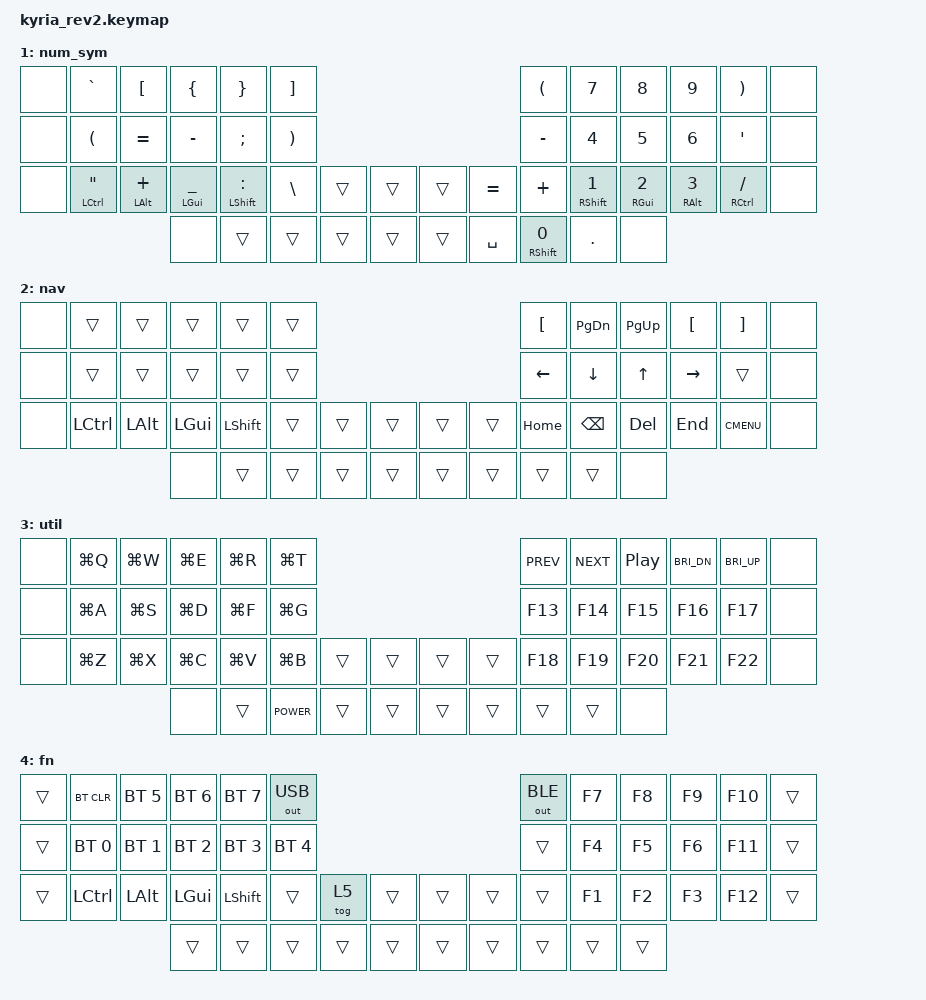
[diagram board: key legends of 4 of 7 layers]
/*
 * Copyright (c) 2020 The ZMK Contributors
 *
 * SPDX-License-Identifier: MIT
 */

#include <behaviors.dtsi>
#include <dt-bindings/zmk/keys.h>
#include <dt-bindings/zmk/bt.h>
#include <dt-bindings/zmk/outputs.h>
#include <dt-bindings/zmk/ext_power.h>

/ {
    behaviors {
        hrml: homerowmods_left {
            compatible = "zmk,behavior-hold-tap";
            label = "HOMEROW_MODS_LEFT";
            #binding-cells = <2>;
            flavor = "tap-preferred";
            require-prior-idle-ms = <120>;
            tapping-term-ms = <200>;
            quick-tap-ms = <100>;
            global-quick-tap;
            bindings =
                <&kp>,
                <&kp>;

            /* hold-trigger-key-positions = <1 2  4  6 7 8 9 10 11  13 14 15 16 19 20 21 22 23 24  26 27 28 29  31 32 33 34 35 36 40 41 42>; */
            hold-trigger-key-positions = <6 7 8 9 10 11 19 20 21 22 23 24 31 32 33 34 35 36 40 41 42>;
            hold-trigger-on-release;
        };
        hrmr: homerowmods_right {
            compatible = "zmk,behavior-hold-tap";
            label = "HOMEROW_MODS_RIGHT";
            #binding-cells = <2>;
            flavor = "tap-preferred";
            require-prior-idle-ms = <120>;
            tapping-term-ms = <200>;
            quick-tap-ms = <100>;
            global-quick-tap;
            bindings =
                <&kp>,
                <&kp>;

            /* hold-trigger-key-positions = <0 1 2 3 4 5 12 13 14 15 16 17 25 26 27 28 29 30  32 33 34 35  37 38 39>; */
            hold-trigger-key-positions = <0 1 2 3 4 5 12 13 14 15 16 17 25 26 27 28 29 30 37 38 39>;
            hold-trigger-on-release;
        };
    };

    combos {
        compatible = "zmk,combos";

        // semicolon_fr {
        //     bindings = <&kp SEMICOLON>;
        //     key-positions = <4 16>;
        //     timeout-ms = <30>;
        // };

        enter_kl {
            bindings = <&kp ENTER>;
            key-positions = <20 21>;
            timeout-ms = <20>;
        };

        backspace_jl {
            bindings = <&kp BACKSPACE>;
            key-positions = <19 21>;
            timeout-ms = <40>;
        };

        backspace_jk {
            bindings = <&kp LA(BACKSPACE)>;
            key-positions = <19 20>;
            timeout-ms = <30>;
        };

        tab_df {
            bindings = <&kp TAB>;
            key-positions = <15 16>;
            timeout-ms = <40>;
            layers = <0 1 2 3>;
        };

        escape_uio {
            bindings = <&kp ESCAPE>;
            key-positions = <7 8 9>;
            timeout-ms = <30>;
        };

        enter_sd {
            bindings = <&kp ENTER>;
            key-positions = <14 15>;
            timeout-ms = <20>;
            layers = <0 1 2 3>;
        };

        space_fg {
            bindings = <&kp SPACE>;
            key-positions = <16 17>;
            timeout-ms = <40>;
        };

        escape_wer {
            bindings = <&kp ESCAPE>;
            key-positions = <2 3 4>;
            timeout-ms = <30>;
            layers = <0 1 2 3>;
        };

        backspace_sf {
            bindings = <&kp BACKSPACE>;
            key-positions = <14 16>;
            timeout-ms = <40>;
            layers = <0 1 2 3>;
        };

        delete_xf {
            bindings = <&kp DELETE>;
            key-positions = <26 16>;
            timeout-ms = <40>;
            layers = <0 1 2 3>;
        };
    };

    conditional_layers {
        compatible = "zmk,conditional-layers";

        tri_layer {
            if-layers = <1 3>;
            then-layer = <4>;
        };
    };

    keymap {
        compatible = "zmk,keymap";

        default_layer {
            bindings = <
  &none          &kp Q         &kp W         &kp E          &kp R       &kp T                                                   &kp Y          &kp U             &kp I           &kp O             &kp P   &none
  &none          &kp A         &kp S         &kp D          &kp F       &kp G                                                   &kp H          &kp J             &kp K           &kp L  &kp SINGLE_QUOTE   &none
  &none  &hrml LCTRL Z  &hrml LALT X  &hrml LGUI C  &hrml LSHFT V       &kp B  &kp LSHFT  &kp LSHFT  &kp LSHFT  &kp LSHFT       &kp N  &hrmr RSHFT M  &hrmr RGUI COMMA  &hrmr RALT DOT  &hrmr RCTRL FSLH   &none
                                             &none      &hrml CAPS LA(LS(LG(F18)))  &kp LSHIFT      &mo 1      &mo 3      &mo 2  &kp SPACE  &kp RSHIFT      &hrmr CAPS LA(LS(LG(F19)))             &none
            >;

            sensor-bindings = <&inc_dec_kp UP DOWN &inc_dec_kp UP DOWN>;
        };

        num_sym {
            bindings = <
  &none        &kp GRAVE         &kp LBKT          &kp LBRC           &kp RBRC  &kp RBKT                                         &kp LPAR          &kp N7         &kp N8         &kp N9          &kp RPAR   &none
  &none         &kp LPAR        &kp EQUAL         &kp MINUS      &kp SEMICOLON  &kp RPAR                                        &kp MINUS          &kp N4         &kp N5         &kp N6           &kp SQT   &none
  &none  &hrml LCTRL DQT  &hrml LALT PLUS  &hrml LGUI UNDER  &hrml LSHFT COLON  &kp BSLH  &trans  &trans  &trans  &kp EQUAL      &kp PLUS  &hrmr RSHFT N1  &hrmr RGUI N2  &hrmr RALT N3  &hrmr RCTRL FSLH   &none
                                                      &none             &trans    &trans  &trans  &trans  &trans  &kp SPACE  &mt RSHFT N0         &kp DOT          &none
            >;
        };

        nav {
            bindings = <
  &none     &trans    &trans    &trans     &trans  &trans                                  &kp LBKT    &kp PG_DN      &kp PG_UP   &kp LBKT   &kp RBKT      &none
  &none     &trans    &trans    &trans     &trans  &trans                                  &kp LEFT    &kp DOWN       &kp UP      &kp RIGHT  &trans        &none
  &none  &kp LCTRL  &kp LALT  &kp LGUI  &kp LSHFT  &trans  &trans  &trans  &trans  &trans  &kp HOME    &kp BACKSPACE  &kp DELETE  &kp END    &kp K_CMENU   &none
                                 &none     &trans  &trans  &trans  &trans  &trans  &trans    &trans       &trans          &none
            >;
        };

        util {
            bindings = <
  &none  &kp LG(Q)  &kp LG(W)  &kp LG(E)  &kp LG(R)    &kp LG(T)                                  &kp C_PREV  &kp C_NEXT  &kp C_PLAY_PAUSE  &kp C_BRI_DN  &kp C_BRI_UP   &none
  &none  &kp LG(A)  &kp LG(S)  &kp LG(D)  &kp LG(F)    &kp LG(G)                                  &kp F13  &kp F14  &kp F15  &kp F16  &kp F17  &none
  &none  &kp LG(Z)  &kp LG(X)  &kp LG(C)  &kp LG(V)    &kp LG(B)  &trans  &trans  &trans  &trans  &kp F18  &kp F19  &kp F20  &kp F21  &kp F22 &none
                                   &none     &trans  &kp C_POWER  &trans  &trans  &trans  &trans      &trans      &trans             &none
            >;
        };

        fn {
            bindings = <
 &trans    &bt BT_CLR  &bt BT_SEL 5  &bt BT_SEL 6  &bt BT_SEL 7  &out OUT_USB                            &out OUT_BLE  &kp F7  &kp F8  &kp F9  &kp F10  &trans
 &trans  &bt BT_SEL 0  &bt BT_SEL 1  &bt BT_SEL 2  &bt BT_SEL 3  &bt BT_SEL 4                                  &trans  &kp F4  &kp F5  &kp F6  &kp F11  &trans
 &trans     &kp LCTRL      &kp LALT      &kp LGUI     &kp LSHFT        &trans  &tog 5  &trans  &trans  &trans  &trans  &kp F1  &kp F2  &kp F3  &kp F12  &trans
                                           &trans        &trans        &trans  &trans  &trans  &trans  &trans  &trans  &trans  &trans
            >;
        };

        game {
            bindings = <
 &trans  &kp TAB       &kp Q         &kp W         &kp E          &kp R                                                         &trans   &trans   &trans   &trans   &trans &trans
 &trans  &kp LCTRL     &kp A         &kp S         &kp D          &kp F                                                         &trans   &trans   &trans   &trans   &trans &trans
 &trans  &kp ENTER     &kp Z         &kp X         &kp C          &kp V        &tog 5     &kp LSHFT  &kp LSHFT  &kp LSHFT       &trans   &trans   &trans   &trans   &trans &trans 
            &none      &kp LALT      &kp LSHFT     &kp SPACE      &mo 6
            >;
        };

        game_alt {
            bindings = <
 &trans  &kp ESCAPE    &kp N7        &kp N8        &kp N9         &kp T                                                         &trans &kp HOME &kp UP   &kp END   &trans &trans 
 &trans  &kp N0        &kp N4        &kp N5        &kp N6         &kp G                                                         &trans &kp LEFT &kp DOWN &kp RIGHT &trans &trans 
 &trans  &kp DOT       &kp N1        &kp N2        &kp N3         &kp B        &tog 5     &kp LSHFT  &kp LSHFT  &kp LSHFT       &trans &trans   &trans   &trans    &trans &trans 
            &none      &trans        &trans        &trans         &trans
            >;
        };
    };
};
